# AE350_4GB register map
Vendor: Andes Technology; Series: AE350; File version: 1.3.0
Registers are 32-bit, read-write, reset 0x0 unless marked. A register's access mark holds for its fields unless they carry their own. Offsets are from the block's base; [hi:lo] are bit positions.

## SPI2 — SPI2 Controller Registers
Base 0xF0F00000
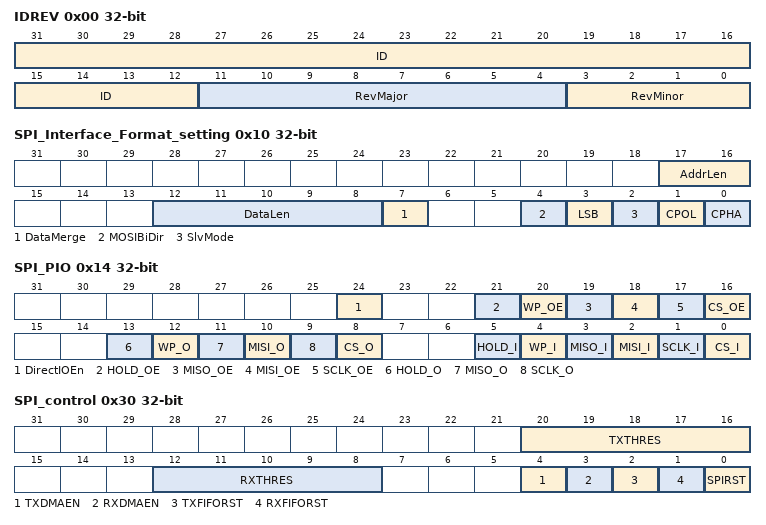
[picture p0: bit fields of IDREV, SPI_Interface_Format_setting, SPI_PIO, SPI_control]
0x00 IDREV ro — ID and Revision Register
  [31:12] ID — ID number for ATCSPI200
  [11:4] RevMajor — Major revision number
  [3:0] RevMinor — Minor revision number
0x10 SPI_Interface_Format_setting
  [17:16] AddrLen — Address length in bytes
  [12:8] DataLen — The length of each data unit in bits
  [7] DataMerge
  [4] MOSIBiDir
  [3] LSB — Transfer data with least significant bit first
  [2] SlvMode — SPI Master/Slave mode selection
  [1] CPOL — SPI Clock Polarity
  [0] CPHA — SPI Clock Phase
0x14 SPI_PIO
  [24] DirectIOEn — Enable Direct IO
  [21] HOLD_OE — Output enable for the SPI Flash hold signal
  [20] WP_OE — Output enable for the SPI Flash write protect signal
  [19] MISO_OE — Output enable fo the SPI MISO signal
  [18] MISI_OE — Output enable fo the SPI MISI signal
  [17] SCLK_OE — Output enable for the SPI SCLK signal
  [16] CS_OE — Output enable for SPI CS (chip select) signal
  [13] HOLD_O — Output value for the SPI Flash hold signal
  [12] WP_O — Output value for the SPI Flash write protect signal
  [11] MISO_O — Output value for the SPI MISO signal
  [10] MISI_O — Output value for the SPI MOSI signal
  [9] SCLK_O — Output value for the SPI SCLK signal
  [8] CS_O — Output value for the SPI CS (chip select) signal
  [5] HOLD_I ro — Status of the SPI Flash hold signal
  [4] WP_I ro — Status of the SPI Flash write protect signal
  [3] MISO_I ro — Status of the SPI MISO signal
  [2] MISI_I ro — Status of the SPI MOSI signal
  [1] SCLK_I ro — Status of the SPI SCLK signal
  [0] CS_I ro — Status of the SPI CS (chip select) signal
0x20 SPI_Transfer_Control
  [30] CmdEn — The SPI command phase enable
  [29] AddrEn — The SPI address phase enable
  [28] AddrFmt — The SPI address phase format
  [27:24] TransMode — The transfer mode
  [23:22] DualQuad — The SPI data phase format
  [23:22] TokenEn — Append an one-byte special token following the address phase for SPI read transfers
  [20:12] WrTranCnt — Transfer count for write data
  [11] TokenValue — The value of the one-byte special token following the address phase for SPI read transfers
  [10:9] DummyCnt — Dummy data count
  [8:0] RdTranCnt — Transfer count for read data
0x24 SPI_command_port
  [7:0] CMD — SPI Command
0x28 SPI_address_port
  [23:0] ADDR — SPI Address
0x2C SPI_data_port
  [31:0] DATA — Data to transmit or the received data
0x30 SPI_control
  [20:16] TXTHRES — Transmit (TX) FIFO Threshold
  [12:8] RXTHRES — Receive (RX) FIFO Threshold
  [4] TXDMAEN — TX DMA enable
  [3] RXDMAEN — RX DMA enable
  [2] TXFIFORST — Transmit FIFO reset
  [1] RXFIFORST — Receive FIFO reset
  [0] SPIRST — SPI reset
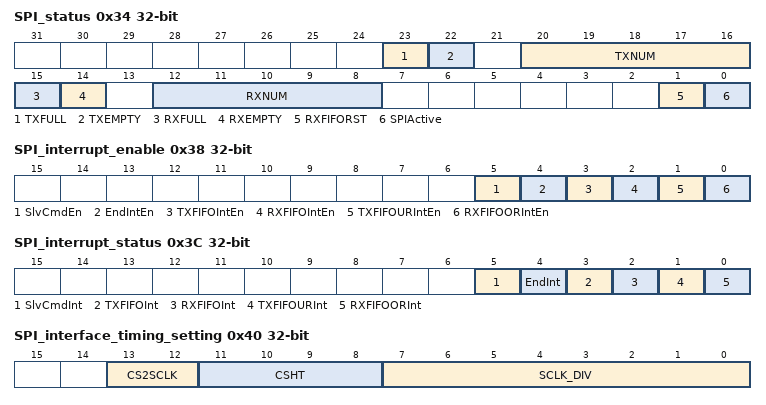
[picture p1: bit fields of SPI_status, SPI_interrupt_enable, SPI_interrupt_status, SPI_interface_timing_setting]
0x34 SPI_status ro
  [23] TXFULL — Transmit FIFO Full flag
  [22] TXEMPTY — Transmit FIFO Empty flag
  [20:16] TXNUM — Number of valid entries in the Transmit FIFO
  [15] RXFULL — Receive FIFO Full flag
  [14] RXEMPTY — Receive FIFO Empty flag
  [12:8] RXNUM — Number of valid entries in the Receive FIFO
  [1] RXFIFORST — Receive FIFO reset
  [0] SPIActive — SPI direct register programming is in progress
0x38 SPI_interrupt_enable — SPI interrupt enable registers
  [5] SlvCmdEn — Enable the Slave Command Interrupt
  [4] EndIntEn — Enable the End of SPI Transfer interrupt
  [3] TXFIFOIntEn — Enable the SPI Transmit FIFO Threshold interrupt
  [2] RXFIFOIntEn — Enable the SPI Receive FIFO Threshold interrupt
  [1] TXFIFOURIntEn — Enable the SPI Transmit FIFO Underrun interrupt
  [0] RXFIFOORIntEn — Enable the SPI Receive FIFO Overrun interrupt
0x3C SPI_interrupt_status wo — SPI interrupt status registers
  [5] SlvCmdInt rw — Slave Command Interrupt
  [4] EndInt rw — End of SPI Transfer interrupt
  [3] TXFIFOInt rw — TX FIFO Threshold interrupt
  [2] RXFIFOInt rw — RX FIFO Threshold interrupt
  [1] TXFIFOURInt rw — TX FIFO Underrun interrupt
  [0] RXFIFOORInt rw — RX FIFO Overrun interrupt
0x40 SPI_interface_timing_setting
  [13:12] CS2SCLK — The minimum time between the edges of SPI CS and the edges of SCLK
  [11:8] CSHT — The minimum time that SPI CS should stay HIGH
  [7:0] SCLK_DIV — The clock frequency ratio between the clock source and SPI interface SCLK
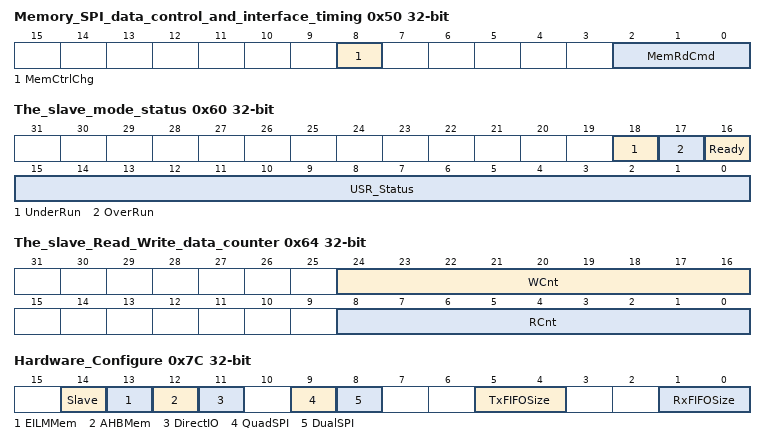
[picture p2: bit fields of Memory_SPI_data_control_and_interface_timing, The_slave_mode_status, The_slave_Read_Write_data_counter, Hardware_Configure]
0x50 Memory_SPI_data_control_and_interface_timing
  [8] MemCtrlChg ro — This bit is set when this register (0x50) or the SPI Interface
  [2:0] MemRdCmd — Selects the SPI command format when serving the memory mapped reads on the AHB/EILM bus
0x60 The_slave_mode_status
  [18] UnderRun — Data underrun occurs in the last transaction
  [17] OverRun — Data overrun occurs in the last transaction
  [16] Ready — Set this bit to indicate that the ATCSPI200 is ready for data transaction
  [15:0] USR_Status — User defined status flags
0x64 The_slave_Read_Write_data_counter ro
  [24:16] WCnt — Slave transmitted data count
  [8:0] RCnt — Slave received data count
0x7C Hardware_Configure ro
  [14] Slave — Support for SPI Slave mode
  [13] EILMMem — Support for memory mapped access (read-only) through EILM bus
  [12] AHBMem — Support for memory mapped access (read-only) through AHB bus
  [11] DirectIO — Support for Direct SPI IO.
  [9] QuadSPI — Support for Quad I/O SPI
  [8] DualSPI — Support for Dual I/O SPI
  [5:4] TxFIFOSize — Depth of TX FIFO
  [1:0] RxFIFOSize — Depth of RX FIFO
